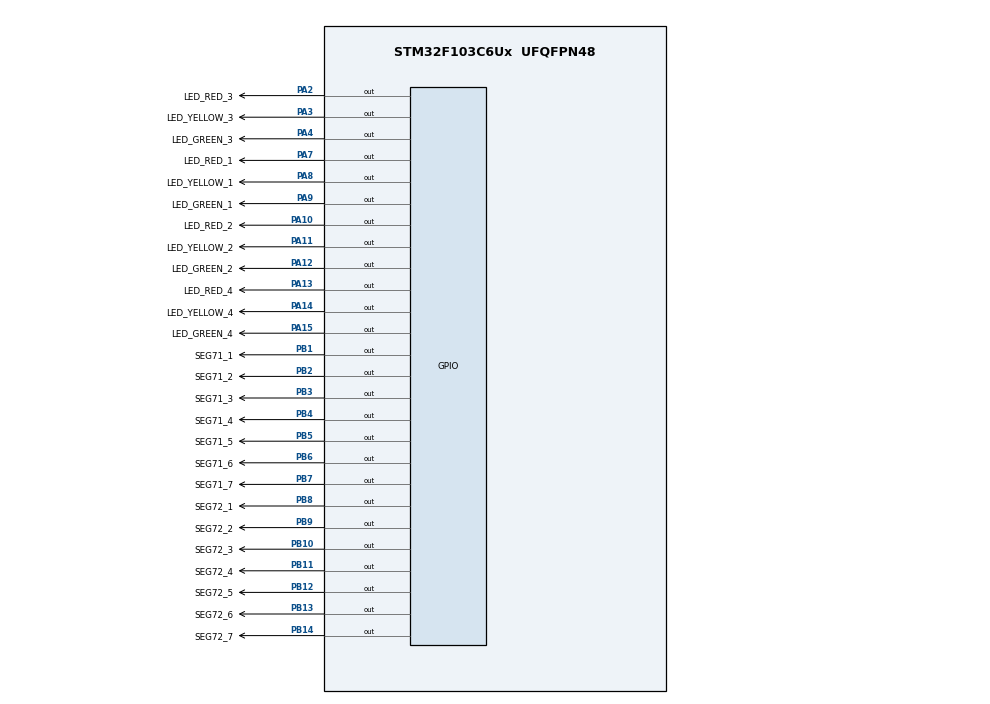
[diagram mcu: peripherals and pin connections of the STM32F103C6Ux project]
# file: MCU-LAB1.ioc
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Mcu.Family=STM32F1
Mcu.Name=STM32F103C6Ux
Mcu.Package=UFQFPN48
NVIC.PriorityGroup=NVIC_PRIORITYGROUP_4
PA10.GPIO_Label=LED_RED_2
PA10.Signal=GPIO_Output
PA11.GPIO_Label=LED_YELLOW_2
PA11.Signal=GPIO_Output
PA12.GPIO_Label=LED_GREEN_2
PA12.Signal=GPIO_Output
PA13.GPIO_Label=LED_RED_4
PA13.Signal=GPIO_Output
PA14.GPIO_Label=LED_YELLOW_4
PA14.Signal=GPIO_Output
PA15.GPIO_Label=LED_GREEN_4
PA15.Signal=GPIO_Output
PA2.GPIO_Label=LED_RED_3
PA2.Signal=GPIO_Output
PA3.GPIO_Label=LED_YELLOW_3
PA3.Signal=GPIO_Output
PA4.GPIO_Label=LED_GREEN_3
PA4.Signal=GPIO_Output
PA7.GPIO_Label=LED_RED_1
PA7.Signal=GPIO_Output
PA8.GPIO_Label=LED_YELLOW_1
PA8.Signal=GPIO_Output
PA9.GPIO_Label=LED_GREEN_1
PA9.Signal=GPIO_Output
PB1.GPIO_Label=SEG71_1
PB1.Signal=GPIO_Output
PB10.GPIO_Label=SEG72_3
PB10.Signal=GPIO_Output
PB11.GPIO_Label=SEG72_4
PB11.Signal=GPIO_Output
PB12.GPIO_Label=SEG72_5
PB12.Signal=GPIO_Output
PB13.GPIO_Label=SEG72_6
PB13.Signal=GPIO_Output
PB14.GPIO_Label=SEG72_7
PB14.Signal=GPIO_Output
PB2.GPIO_Label=SEG71_2
PB2.Signal=GPIO_Output
PB3.GPIO_Label=SEG71_3
PB3.Signal=GPIO_Output
PB4.GPIO_Label=SEG71_4
PB4.Signal=GPIO_Output
PB5.GPIO_Label=SEG71_5
PB5.Signal=GPIO_Output
PB6.GPIO_Label=SEG71_6
PB6.Signal=GPIO_Output
PB7.GPIO_Label=SEG71_7
PB7.Signal=GPIO_Output
PB8.GPIO_Label=SEG72_1
PB8.Signal=GPIO_Output
PB9.GPIO_Label=SEG72_2
PB9.Signal=GPIO_Output
ProjectManager.HeapSize=0x200
ProjectManager.StackSize=0x400
ProjectManager.TargetToolchain=STM32CubeIDE
RCC.APB1Freq_Value=8000000
RCC.APB2Freq_Value=8000000
board=custom

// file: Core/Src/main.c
/* USER CODE BEGIN Header */
/**
  ******************************************************************************
  * @file           : main.c
  * @brief          : Main program body
  ******************************************************************************
  * @attention
  *
  * Copyright (c) 2024 STMicroelectronics.
  * All rights reserved.
  *
  * This software is licensed under terms that can be found in the LICENSE file
  * in the root directory of this software component.
  * If no LICENSE file comes with this software, it is provided AS-IS.
  *
  ******************************************************************************
  */
/* USER CODE END Header */
#include "main.h"

/* USER CODE BEGIN Includes */
#include "ex10.h"
/* USER CODE END Includes */

void SystemClock_Config(void);
static void MX_GPIO_Init(void);

int main(void)
{

  /* MCU Configuration--------------------------------------------------------*/

  /* Reset of all peripherals, Initializes the Flash interface and the Systick. */
  HAL_Init();

  /* Configure the system clock */
  SystemClock_Config();

  /* Initialize all configured peripherals */
  MX_GPIO_Init();
  /* USER CODE BEGIN 2 */
  init_ex10();
  /* USER CODE END 2 */

  /* Infinite loop */
  /* USER CODE BEGIN WHILE */
  while (1)
  {
	  run_ex10();
	  HAL_Delay(1000);
    /* USER CODE END WHILE */

  }
}

void SystemClock_Config(void)
{
  RCC_OscInitTypeDef RCC_OscInitStruct = {0};
  RCC_ClkInitTypeDef RCC_ClkInitStruct = {0};

  /** Initializes the RCC Oscillators according to the specified parameters
  * in the RCC_OscInitTypeDef structure.
  */
  RCC_OscInitStruct.OscillatorType = RCC_OSCILLATORTYPE_HSI;
  RCC_OscInitStruct.HSIState = RCC_HSI_ON;
  RCC_OscInitStruct.HSICalibrationValue = RCC_HSICALIBRATION_DEFAULT;
  RCC_OscInitStruct.PLL.PLLState = RCC_PLL_NONE;
  if (HAL_RCC_OscConfig(&RCC_OscInitStruct) != HAL_OK)
  {
    Error_Handler();
  }

  /** Initializes the CPU, AHB and APB buses clocks
  */
  RCC_ClkInitStruct.ClockType = RCC_CLOCKTYPE_HCLK|RCC_CLOCKTYPE_SYSCLK
                              |RCC_CLOCKTYPE_PCLK1|RCC_CLOCKTYPE_PCLK2;
  RCC_ClkInitStruct.SYSCLKSource = RCC_SYSCLKSOURCE_HSI;
  RCC_ClkInitStruct.AHBCLKDivider = RCC_SYSCLK_DIV1;
  RCC_ClkInitStruct.APB1CLKDivider = RCC_HCLK_DIV1;
  RCC_ClkInitStruct.APB2CLKDivider = RCC_HCLK_DIV1;

  if (HAL_RCC_ClockConfig(&RCC_ClkInitStruct, FLASH_LATENCY_0) != HAL_OK)
  {
    Error_Handler();
  }
}

static void MX_GPIO_Init(void)
{
  GPIO_InitTypeDef GPIO_InitStruct = {0};

  /* GPIO Ports Clock Enable */
  __HAL_RCC_GPIOA_CLK_ENABLE();

  /*Configure GPIO pin Output Level */
  HAL_GPIO_WritePin(GPIOA, LED_RED_3_Pin|LED_YELLOW_3_Pin|LED_GREEN_3_Pin|LED_RED_1_Pin
                          |LED_YELLOW_1_Pin|LED_GREEN_1_Pin|LED_RED_2_Pin|LED_YELLOW_2_Pin
                          |LED_GREEN_2_Pin|LED_RED_4_Pin|LED_YELLOW_4_Pin|LED_GREEN_4_Pin, GPIO_PIN_RESET);

  /*Configure GPIO pins : LED_RED_3_Pin LED_YELLOW_3_Pin LED_GREEN_3_Pin LED_RED_1_Pin
                           LED_YELLOW_1_Pin LED_GREEN_1_Pin LED_RED_2_Pin LED_YELLOW_2_Pin
                           LED_GREEN_2_Pin LED_RED_4_Pin LED_YELLOW_4_Pin LED_GREEN_4_Pin */
  GPIO_InitStruct.Pin = LED_RED_3_Pin|LED_YELLOW_3_Pin|LED_GREEN_3_Pin|LED_RED_1_Pin
                          |LED_YELLOW_1_Pin|LED_GREEN_1_Pin|LED_RED_2_Pin|LED_YELLOW_2_Pin
                          |LED_GREEN_2_Pin|LED_RED_4_Pin|LED_YELLOW_4_Pin|LED_GREEN_4_Pin;
  GPIO_InitStruct.Mode = GPIO_MODE_OUTPUT_PP;
  GPIO_InitStruct.Pull = GPIO_NOPULL;
  GPIO_InitStruct.Speed = GPIO_SPEED_FREQ_LOW;
  HAL_GPIO_Init(GPIOA, &GPIO_InitStruct);

}

void Error_Handler(void)
{
  __disable_irq();
  while (1)
  {
  }
}
